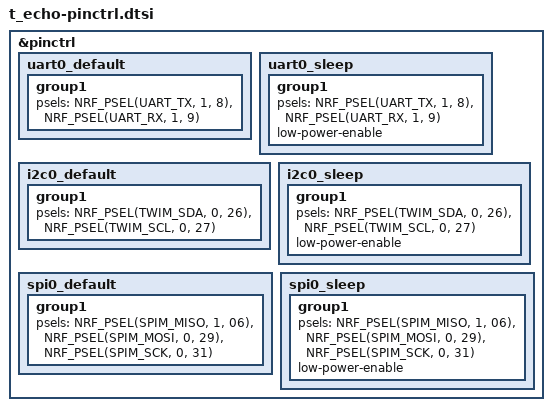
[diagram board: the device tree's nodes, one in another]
/*
 * Copyright (c) 2022 Nordic Semiconductor
 * SPDX-License-Identifier: Apache-2.0
 */

&pinctrl {
	uart0_default: uart0_default {
		group1 {
			psels = <NRF_PSEL(UART_TX, 1, 8)>,
				<NRF_PSEL(UART_RX, 1, 9)>;
		};
	};

	uart0_sleep: uart0_sleep {
		group1 {
			psels = <NRF_PSEL(UART_TX, 1, 8)>,
				<NRF_PSEL(UART_RX, 1, 9)>;
			low-power-enable;
		};
	};

	i2c0_default: i2c0_default {
		group1 {
			psels = <NRF_PSEL(TWIM_SDA, 0, 26)>,
				<NRF_PSEL(TWIM_SCL, 0, 27)>;
		};
	};

	i2c0_sleep: i2c0_sleep {
		group1 {
			psels = <NRF_PSEL(TWIM_SDA, 0, 26)>,
				<NRF_PSEL(TWIM_SCL, 0, 27)>;
			low-power-enable;
		};
	};

	spi0_default: spi0_default {
		group1 {
			psels = <NRF_PSEL(SPIM_MISO, 1, 06)>,
				<NRF_PSEL(SPIM_MOSI, 0, 29)>,
				<NRF_PSEL(SPIM_SCK, 0, 31)>;
		};
	};

	spi0_sleep: spi0_sleep {
		group1 {
			psels = <NRF_PSEL(SPIM_MISO, 1, 06)>,
				<NRF_PSEL(SPIM_MOSI, 0, 29)>,
				<NRF_PSEL(SPIM_SCK, 0, 31)>;
			low-power-enable;
		};
	};
};
